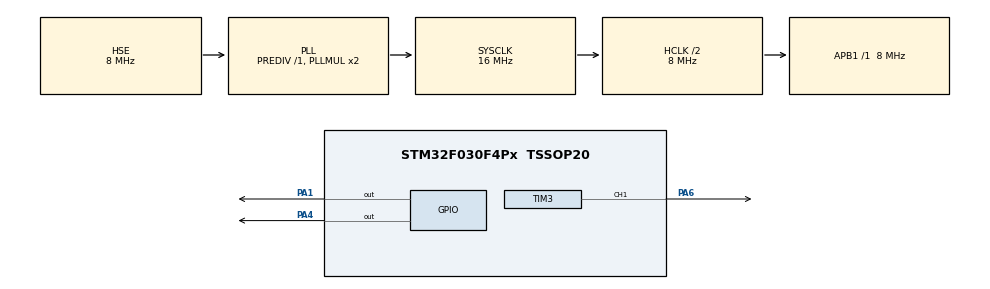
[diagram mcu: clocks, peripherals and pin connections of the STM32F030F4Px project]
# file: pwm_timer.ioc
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Mcu.Family=STM32F0
Mcu.Name=STM32F030F4Px
Mcu.Package=TSSOP20
PA1.Signal=GPIO_Output
PA4.Signal=GPIO_Output
PA6.Signal=S_TIM3_CH1
PF0-OSC_IN.Mode=HSE-External-Oscillator
PF0-OSC_IN.Signal=RCC_OSC_IN
PF1-OSC_OUT.Mode=HSE-External-Oscillator
PF1-OSC_OUT.Signal=RCC_OSC_OUT
ProjectManager.HeapSize=0x200
ProjectManager.StackSize=0x400
ProjectManager.TargetToolchain=STM32CubeIDE
RCC.AHBCLKDivider=RCC_SYSCLK_DIV2
RCC.AHBFreq_Value=8000000
RCC.APB1Freq_Value=8000000
RCC.APB1TimFreq_Value=8000000
RCC.HCLKFreq_Value=8000000
RCC.PLLSourceVirtual=RCC_PLLSOURCE_HSE
RCC.RCC_PERIPHCLK_RTCVar=RCC_PERIPHCLK_RTC
RCC.SYSCLKFreq_VALUE=16000000
RCC.SYSCLKSource=RCC_SYSCLKSOURCE_PLLCLK
SH.S_TIM3_CH1.0=TIM3_CH1,PWM Generation1 CH1
TIM3.Channel-PWM\ Generation1\ CH1=TIM_CHANNEL_1
TIM3.Period=65535-1
TIM3.Prescaler=1000-1
VP_TIM3_VS_ClockSourceINT.Mode=Internal
board=custom

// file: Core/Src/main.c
/* USER CODE BEGIN Header */
/**
  ******************************************************************************
  * @file           : main.c
  * @brief          : Main program body
  ******************************************************************************
  * @attention
  *
  * Copyright (c) 2023 STMicroelectronics.
  * All rights reserved.
  *
  * This software is licensed under terms that can be found in the LICENSE file
  * in the root directory of this software component.
  * If no LICENSE file comes with this software, it is provided AS-IS.
  *
  ******************************************************************************
  */
/* USER CODE END Header */
#include "main.h"

TIM_HandleTypeDef htim3;

void SystemClock_Config(void);
static void MX_GPIO_Init(void);
static void MX_TIM3_Init(void);

int main(void)
{
  /* USER CODE BEGIN 1 */
	uint16_t timer_val;
  /* USER CODE END 1 */

  /* MCU Configuration--------------------------------------------------------*/

  /* Reset of all peripherals, Initializes the Flash interface and the Systick. */
  HAL_Init();

  /* Configure the system clock */
  SystemClock_Config();

  /* Initialize all configured peripherals */
  MX_GPIO_Init();
  MX_TIM3_Init();

  /* Infinite loop */
  /* USER CODE BEGIN WHILE */
  HAL_TIM_Base_Start(&htim3);
  while (1)
   {
     /* USER CODE END WHILE */
 	  HAL_GPIO_WritePin(GPIOA, GPIO_PIN_4, 1);
 	  HAL_Delay(1000);
 	  HAL_GPIO_WritePin(GPIOA, GPIO_PIN_4, 0);
 	  HAL_Delay(1000);
     /* USER CODE BEGIN 3 */
   }
     /* USER CODE END 2 */
//   timer_val=__HAL_TIM_GET_COUNTER(&htim3);
//   HAL_GPIO_WritePin(GPIOA,GPIO_PIN_1,0);
     /* Infinite loop */
     /* USER CODE BEGIN WHILE */

    /* USER CODE END WHILE */

    /* USER CODE BEGIN 3 */

    /* USER CODE BEGIN 3 */

//       while (1)
//       {
//       /* USER CODE END WHILE */
//       	if((__HAL_TIM_GET_COUNTER(&htim3)-timer_val)>=5000)
//       	{
//       				timer_val=__HAL_TIM_GET_COUNTER(&htim3);
//       	}
//       /* USER CODE BEGIN 3 */
//     }
  /* USER CODE BEGIN WHILE */

  /* USER CODE END 3 */
}

void SystemClock_Config(void)
{
  RCC_OscInitTypeDef RCC_OscInitStruct = {0};
  RCC_ClkInitTypeDef RCC_ClkInitStruct = {0};

  /** Initializes the RCC Oscillators according to the specified parameters
  * in the RCC_OscInitTypeDef structure.
  */
  RCC_OscInitStruct.OscillatorType = RCC_OSCILLATORTYPE_HSE;
  RCC_OscInitStruct.HSEState = RCC_HSE_ON;
  RCC_OscInitStruct.PLL.PLLState = RCC_PLL_ON;
  RCC_OscInitStruct.PLL.PLLSource = RCC_PLLSOURCE_HSE;
  RCC_OscInitStruct.PLL.PLLMUL = RCC_PLL_MUL2;
  RCC_OscInitStruct.PLL.PREDIV = RCC_PREDIV_DIV1;
  if (HAL_RCC_OscConfig(&RCC_OscInitStruct) != HAL_OK)
  {
    Error_Handler();
  }

  /** Initializes the CPU, AHB and APB buses clocks
  */
  RCC_ClkInitStruct.ClockType = RCC_CLOCKTYPE_HCLK|RCC_CLOCKTYPE_SYSCLK
                              |RCC_CLOCKTYPE_PCLK1;
  RCC_ClkInitStruct.SYSCLKSource = RCC_SYSCLKSOURCE_PLLCLK;
  RCC_ClkInitStruct.AHBCLKDivider = RCC_SYSCLK_DIV2;
  RCC_ClkInitStruct.APB1CLKDivider = RCC_HCLK_DIV1;

  if (HAL_RCC_ClockConfig(&RCC_ClkInitStruct, FLASH_LATENCY_0) != HAL_OK)
  {
    Error_Handler();
  }
}

static void MX_TIM3_Init(void)
{

  TIM_ClockConfigTypeDef sClockSourceConfig = {0};
  TIM_MasterConfigTypeDef sMasterConfig = {0};
  TIM_OC_InitTypeDef sConfigOC = {0};

  htim3.Instance = TIM3;
  htim3.Init.Prescaler = 1000-1;
  htim3.Init.CounterMode = TIM_COUNTERMODE_UP;
  htim3.Init.Period = 65535-1;
  htim3.Init.ClockDivision = TIM_CLOCKDIVISION_DIV1;
  htim3.Init.AutoReloadPreload = TIM_AUTORELOAD_PRELOAD_DISABLE;
  if (HAL_TIM_Base_Init(&htim3) != HAL_OK)
  {
    Error_Handler();
  }
  sClockSourceConfig.ClockSource = TIM_CLOCKSOURCE_INTERNAL;
  if (HAL_TIM_ConfigClockSource(&htim3, &sClockSourceConfig) != HAL_OK)
  {
    Error_Handler();
  }
  if (HAL_TIM_PWM_Init(&htim3) != HAL_OK)
  {
    Error_Handler();
  }
  sMasterConfig.MasterOutputTrigger = TIM_TRGO_RESET;
  sMasterConfig.MasterSlaveMode = TIM_MASTERSLAVEMODE_DISABLE;
  if (HAL_TIMEx_MasterConfigSynchronization(&htim3, &sMasterConfig) != HAL_OK)
  {
    Error_Handler();
  }
  sConfigOC.OCMode = TIM_OCMODE_PWM1;
  sConfigOC.Pulse = 0;
  sConfigOC.OCPolarity = TIM_OCPOLARITY_HIGH;
  sConfigOC.OCFastMode = TIM_OCFAST_DISABLE;
  if (HAL_TIM_PWM_ConfigChannel(&htim3, &sConfigOC, TIM_CHANNEL_1) != HAL_OK)
  {
    Error_Handler();
  }
  HAL_TIM_MspPostInit(&htim3);

}

static void MX_GPIO_Init(void)
{
  GPIO_InitTypeDef GPIO_InitStruct = {0};

  /* GPIO Ports Clock Enable */
  __HAL_RCC_GPIOF_CLK_ENABLE();
  __HAL_RCC_GPIOA_CLK_ENABLE();

  /*Configure GPIO pin Output Level */
  HAL_GPIO_WritePin(GPIOA, GPIO_PIN_1|GPIO_PIN_4, GPIO_PIN_RESET);

  /*Configure GPIO pins : PA1 PA4 */
  GPIO_InitStruct.Pin = GPIO_PIN_1|GPIO_PIN_4;
  GPIO_InitStruct.Mode = GPIO_MODE_OUTPUT_PP;
  GPIO_InitStruct.Pull = GPIO_NOPULL;
  GPIO_InitStruct.Speed = GPIO_SPEED_FREQ_LOW;
  HAL_GPIO_Init(GPIOA, &GPIO_InitStruct);

}

void Error_Handler(void)
{
  __disable_irq();
  while (1)
  {
  }
}
